# ATSAML21G16A register map
Vendor: Atmel Corporation; Series: SAML21; File version: A
CPU: CM0+ r0p1, little endian, no MPU, no FPU, VTOR, 2 interrupt priority bits
Registers are 32-bit, read-write, reset 0x0 unless marked. A register's access mark holds for its fields unless they carry their own. Offsets are from the block's base; [hi:lo] are bit positions; {n}, {i} and the like mark numbered series; 'fields as' and 'values as' point back to an identical list.

## MCLK — Main Clock
Base 0x40000400; register names take the prefix MCLK_
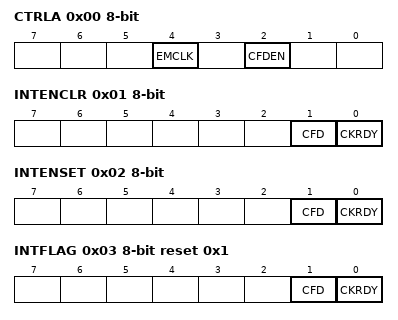
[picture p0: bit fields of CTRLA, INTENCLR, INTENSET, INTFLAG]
0x00 CTRLA 8-bit — Control A
  [4] EMCLK — Emergency Clock Select
  [2] CFDEN — Clock Failure Detector Enable
0x01 INTENCLR 8-bit — Interrupt Enable Clear
  [1] CFD — Clock Failure Detector Interrupt Enable
  [0] CKRDY — Clock Ready Interrupt Enable
0x02 INTENSET 8-bit — Interrupt Enable Set
  fields as INTENCLR
0x03 INTFLAG 8-bit reset 0x1 — Interrupt Flag Status and Clear
  [1] CFD — Clock Failure Detector
  [0] CKRDY — Clock Ready
0x04 CPUDIV 8-bit reset 0x1 — CPU Clock Division
  [7:0] CPUDIV — CPU Clock Division Factor
    1=DIV1 (Divide by 1); 2=DIV2 (Divide by 2); 4=DIV4 (Divide by 4); 8=DIV8 (Divide by 8); 16=DIV16 (Divide by 16); 32=DIV32 (Divide by 32); 64=DIV64 (Divide by 64); 128=DIV128 (Divide by 128)
0x05 LPDIV 8-bit reset 0x1 — Low-Power Clock Division
  [7:0] LPDIV — Low-Power Clock Division Factor
    values as CPUDIV.CPUDIV
0x06 BUPDIV 8-bit reset 0x1 — Backup Clock Division
  [7:0] BUPDIV — Backup Clock Division Factor
    values as CPUDIV.CPUDIV
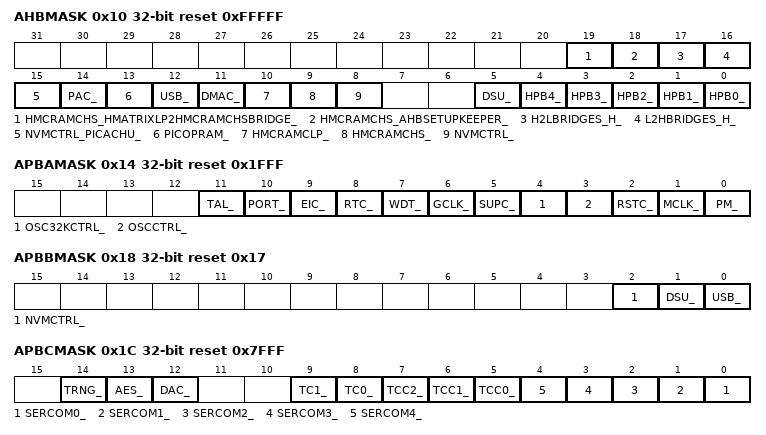
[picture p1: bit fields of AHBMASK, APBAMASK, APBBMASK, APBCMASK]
0x10 AHBMASK reset 0xFFFFF
  [19] HMCRAMCHS_HMATRIXLP2HMCRAMCHSBRIDGE_ — HMCRAMCHS_HMATRIXLP2HMCRAMCHSBRIDGE AHB Clock Mask
  [18] HMCRAMCHS_AHBSETUPKEEPER_ — HMCRAMCHS_AHBSETUPKEEPER AHB Clock Mask
  [17] H2LBRIDGES_H_ — H2LBRIDGES_H AHB Clock Mask
  [16] L2HBRIDGES_H_ — L2HBRIDGES_H AHB Clock Mask
  [15] NVMCTRL_PICACHU_ — NVMCTRL_PICACHU AHB Clock Mask
  [14] PAC_ — PAC AHB Clock Mask
  [13] PICOPRAM_ — PICOPRAM AHB Clock Mask
  [12] USB_ — USB AHB Clock Mask
  [11] DMAC_ — DMAC AHB Clock Mask
  [10] HMCRAMCLP_ — HMCRAMCLP AHB Clock Mask
  [9] HMCRAMCHS_ — HMCRAMCHS AHB Clock Mask
  [8] NVMCTRL_ — NVMCTRL AHB Clock Mask
  [5] DSU_ — DSU AHB Clock Mask
  [n] HPB{n}_ (n=0..4) — HPB{n} AHB Clock Mask
0x14 APBAMASK reset 0x1FFF
  [11] TAL_ — TAL APB Clock Enable
  [10] PORT_ — PORT APB Clock Enable
  [9] EIC_ — EIC APB Clock Enable
  [8] RTC_ — RTC APB Clock Enable
  [7] WDT_ — WDT APB Clock Enable
  [6] GCLK_ — GCLK APB Clock Enable
  [5] SUPC_ — SUPC APB Clock Enable
  [4] OSC32KCTRL_ — OSC32KCTRL APB Clock Enable
  [3] OSCCTRL_ — OSCCTRL APB Clock Enable
  [2] RSTC_ — RSTC APB Clock Enable
  [1] MCLK_ — MCLK APB Clock Enable
  [0] PM_ — PM APB Clock Enable
0x18 APBBMASK reset 0x17
  [2] NVMCTRL_ — NVMCTRL APB Clock Enable
  [1] DSU_ — DSU APB Clock Enable
  [0] USB_ — USB APB Clock Enable
0x1C APBCMASK reset 0x7FFF
  [14] TRNG_ — TRNG APB Clock Enable
  [13] AES_ — AES APB Clock Enable
  [12] DAC_ — DAC APB Clock Enable
  [9] TC1_ — TC1 APB Clock Enable
  [8] TC0_ — TC0 APB Clock Enable
  [7] TCC2_ — TCC2 APB Clock Enable
  [6] TCC1_ — TCC1 APB Clock Enable
  [5] TCC0_ — TCC0 APB Clock Enable
  [n] SERCOM{n}_ (n=0..4) — SERCOM{n} APB Clock Enable
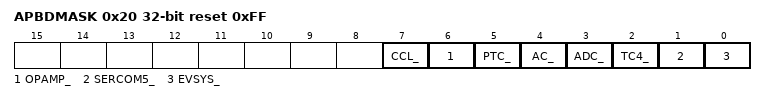
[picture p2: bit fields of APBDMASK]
0x20 APBDMASK reset 0xFF
  [7] CCL_ — CCL APB Clock Enable
  [6] OPAMP_ — OPAMP APB Clock Enable
  [5] PTC_ — PTC APB Clock Enable
  [4] AC_ — AC APB Clock Enable
  [3] ADC_ — ADC APB Clock Enable
  [2] TC4_ — TC4 APB Clock Enable
  [1] SERCOM5_ — SERCOM5 APB Clock Enable
  [0] EVSYS_ — EVSYS APB Clock Enable
0x24 APBEMASK reset 0xD
  [0] PAC_ — PAC APB Clock Enable

## MTB — Cortex-M0+ Micro-Trace Buffer
Base 0x41006000; register names take the prefix MTB_
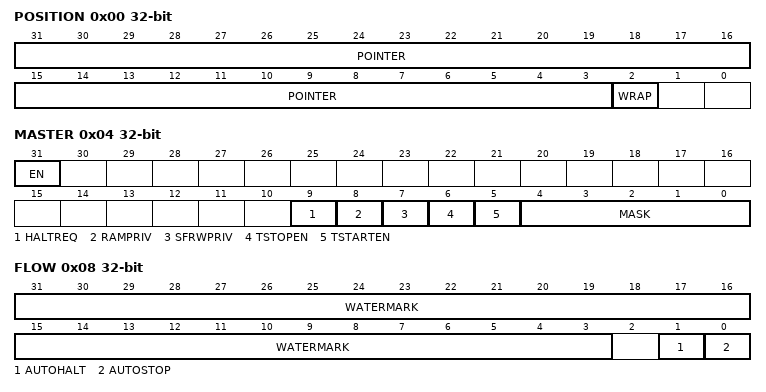
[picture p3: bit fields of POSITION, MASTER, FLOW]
0x00 POSITION — MTB Position
  [31:3] POINTER — Trace Packet Location Pointer
  [2] WRAP — Pointer Value Wraps
0x04 MASTER — MTB Master
  [31] EN — Main Trace Enable
  [9] HALTREQ — Halt Request
  [8] RAMPRIV — SRAM Privilege
  [7] SFRWPRIV — Special Function Register Write Privilege
  [6] TSTOPEN — Trace Stop Input Enable
  [5] TSTARTEN — Trace Start Input Enable
  [4:0] MASK — Maximum Value of the Trace Buffer in SRAM
0x08 FLOW — MTB Flow
  [31:3] WATERMARK — Watermark value
  [1] AUTOHALT — Auto Halt Request
  [0] AUTOSTOP — Auto Stop Tracing
0x0C BASE ro — MTB Base
0xF00 ITCTRL — MTB Integration Mode Control
0xFA0 CLAIMSET — MTB Claim Set
0xFA4 CLAIMCLR — MTB Claim Clear
0xFB0 LOCKACCESS — MTB Lock Access
0xFB4 LOCKSTATUS ro — MTB Lock Status
0xFB8 AUTHSTATUS ro — MTB Authentication Status
0xFBC DEVARCH ro — MTB Device Architecture
0xFC8 DEVID ro — MTB Device Configuration
0xFCC DEVTYPE ro — MTB Device Type
{0xFC0+4i} PID{i} ro (i=4..7) — Peripheral Identification {i}
{0xFE0+4i} PID{i} ro (i=0..3) — Peripheral Identification {i}
{0xFF0+4i} CID{i} ro (i=0..3) — Component Identification {i}

## Notices in the file
Atmel Microcontroller Software Support
Copyright (c) 2015, Atmel Corporation
All rights reserved.
Redistribution and use in source and binary forms, with or without
modification, are permitted provided that the following condition is met:
- Redistributions of source code must retain the above copyright notice,
this list of conditions and the disclaimer below.
Atmel's name may not be used to endorse or promote products derived from
this software without specific prior written permission.
DISCLAIMER: THIS SOFTWARE IS PROVIDED BY ATMEL "AS IS" AND ANY EXPRESS OR
IMPLIED WARRANTIES, INCLUDING, BUT NOT LIMITED TO, THE IMPLIED WARRANTIES OF
MERCHANTABILITY, FITNESS FOR A PARTICULAR PURPOSE AND NON-INFRINGEMENT ARE
DISCLAIMED. IN NO EVENT SHALL ATMEL BE LIABLE FOR ANY DIRECT, INDIRECT,
INCIDENTAL, SPECIAL, EXEMPLARY, OR CONSEQUENTIAL DAMAGES (INCLUDING, BUT NOT
LIMITED TO, PROCUREMENT OF SUBSTITUTE GOODS OR SERVICES; LOSS OF USE, DATA,
OR PROFITS; OR BUSINESS INTERRUPTION) HOWEVER CAUSED AND ON ANY THEORY OF
LIABILITY, WHETHER IN CONTRACT, STRICT LIABILITY, OR TORT (INCLUDING
NEGLIGENCE OR OTHERWISE) ARISING IN ANY WAY OUT OF THE USE OF THIS SOFTWARE,
EVEN IF ADVISED OF THE POSSIBILITY OF SUCH DAMAGE.
